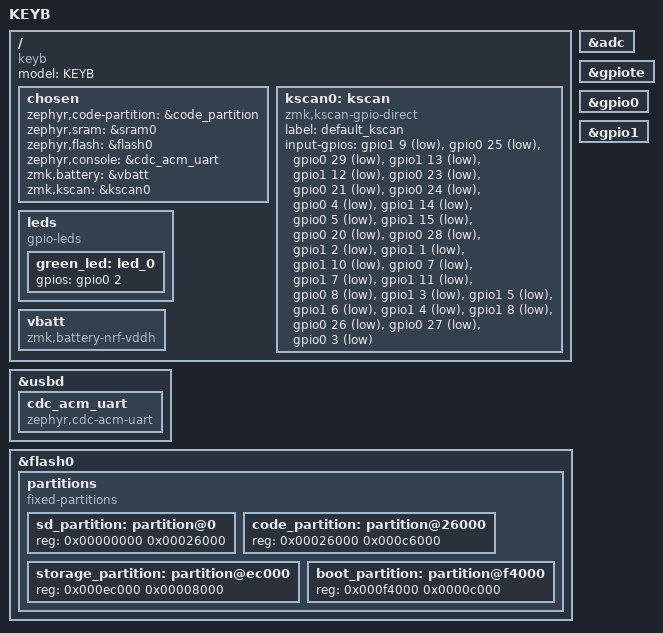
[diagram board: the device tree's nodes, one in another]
/*
 * Copyright (c) 2021 The ZMK Contributors
 *
 * SPDX-License-Identifier: MIT
 */

/dts-v1/;
#include <nordic/nrf52840_qiaa.dtsi>

/ {
    model = "KEYB";
    compatible = "keyb";

    chosen {
        zephyr,code-partition = &code_partition;
        zephyr,sram = &sram0;
        zephyr,flash = &flash0;
        zephyr,console = &cdc_acm_uart;
        zmk,battery = &vbatt;
        zmk,kscan = &kscan0;
    };


    kscan0: kscan {
		compatible = "zmk,kscan-gpio-direct";
        label = "default_kscan";

		input-gpios =
            <&gpio1 9  (GPIO_ACTIVE_LOW | GPIO_PULL_UP)>,   // Top-most row
            <&gpio0 25 (GPIO_ACTIVE_LOW | GPIO_PULL_UP)>,
            <&gpio0 29 (GPIO_ACTIVE_LOW | GPIO_PULL_UP)>,
            <&gpio1 13 (GPIO_ACTIVE_LOW | GPIO_PULL_UP)>,
            <&gpio1 12 (GPIO_ACTIVE_LOW | GPIO_PULL_UP)>,
            <&gpio0 23 (GPIO_ACTIVE_LOW | GPIO_PULL_UP)>,  

            <&gpio0 21 (GPIO_ACTIVE_LOW | GPIO_PULL_UP)>,   // Top row
            <&gpio0 24 (GPIO_ACTIVE_LOW | GPIO_PULL_UP)>,
            <&gpio0 4  (GPIO_ACTIVE_LOW | GPIO_PULL_UP)>,
            <&gpio1 14 (GPIO_ACTIVE_LOW | GPIO_PULL_UP)>,
            <&gpio0 5  (GPIO_ACTIVE_LOW | GPIO_PULL_UP)>,
            <&gpio1 15 (GPIO_ACTIVE_LOW | GPIO_PULL_UP)>,
            
            <&gpio0 20  (GPIO_ACTIVE_LOW | GPIO_PULL_UP)>,  // Middle row
            <&gpio0 28  (GPIO_ACTIVE_LOW | GPIO_PULL_UP)>,
            <&gpio1 2   (GPIO_ACTIVE_LOW | GPIO_PULL_UP)>,
            <&gpio1 1   (GPIO_ACTIVE_LOW | GPIO_PULL_UP)>,
            <&gpio1 10  (GPIO_ACTIVE_LOW | GPIO_PULL_UP)>,
            <&gpio0 7   (GPIO_ACTIVE_LOW | GPIO_PULL_UP)>,

            <&gpio1 7   (GPIO_ACTIVE_LOW | GPIO_PULL_UP)>,  // Bottom Row
            <&gpio1 11  (GPIO_ACTIVE_LOW | GPIO_PULL_UP)>,
            <&gpio0 8   (GPIO_ACTIVE_LOW | GPIO_PULL_UP)>,
            <&gpio1 3   (GPIO_ACTIVE_LOW | GPIO_PULL_UP)>,
            <&gpio1 5   (GPIO_ACTIVE_LOW | GPIO_PULL_UP)>,
            <&gpio1 6   (GPIO_ACTIVE_LOW | GPIO_PULL_UP)>,

            <&gpio1 4   (GPIO_ACTIVE_LOW | GPIO_PULL_UP)>,  // Thumb Cluster
            <&gpio1 8   (GPIO_ACTIVE_LOW | GPIO_PULL_UP)>,
            <&gpio0 26  (GPIO_ACTIVE_LOW | GPIO_PULL_UP)>,
            <&gpio0 27  (GPIO_ACTIVE_LOW | GPIO_PULL_UP)>,
            <&gpio0 3   (GPIO_ACTIVE_LOW | GPIO_PULL_UP)>;
	};

    leds {
        compatible = "gpio-leds";
        green_led: led_0 {
            gpios = <&gpio0 2 GPIO_ACTIVE_HIGH>;
        };
    };

    vbatt: vbatt {
        compatible = "zmk,battery-nrf-vddh";
    };
};

&adc {
    status = "okay";
};

&gpiote {
    status = "okay";
};

&gpio0 {
    status = "okay";
};

&gpio1 {
    status = "okay";
};

&usbd {
    status = "okay";
    cdc_acm_uart: cdc_acm_uart {
        compatible = "zephyr,cdc-acm-uart";
    };
};

&flash0 {
    /*
     * For more information, see:
     * http://docs.zephyrproject.org/latest/devices/dts/flash_partitions.html
     */
    partitions {
        compatible = "fixed-partitions";
        #address-cells = <1>;
        #size-cells = <1>;

        sd_partition: partition@0 {
            reg = <0x00000000 0x00026000>;
        };
        code_partition: partition@26000 {
            reg = <0x00026000 0x000c6000>;
        };

        /*
         * The flash starting at 0x000ec000 and ending at
         * 0x000f3fff is reserved for use by the application.
         */

        /*
         * Storage partition will be used by FCB/LittleFS/NVS
         * if enabled.
         */
        storage_partition: partition@ec000 {
            reg = <0x000ec000 0x00008000>;
        };

        boot_partition: partition@f4000 {
            reg = <0x000f4000 0x0000c000>;
        };
    };
};
